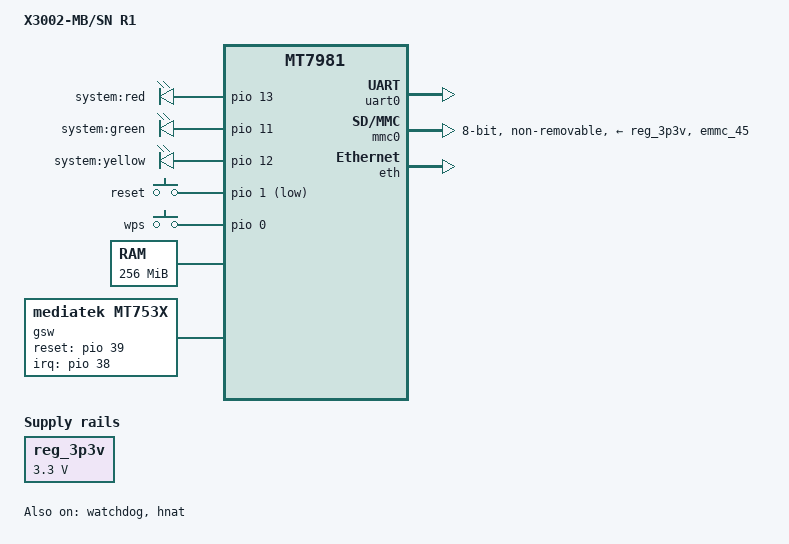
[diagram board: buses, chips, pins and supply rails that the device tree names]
/dts-v1/;
#include "mt7981.dtsi"
/ {
	model = "X3002-MB/SN R1";
	compatible = "sn,r1", "mediatek,mt7981";

	chosen {
		bootargs = "console=ttyS0,115200n1 loglevel=8  \
				earlycon=uart8250,mmio32,0x11002000 \
				root=PARTLABEL=rootfs rootfstype=squashfs,f2fs";
	};

	aliases {
		led-boot = &red_led;
		led-failsafe = &red_led;
		led-running = &green_led;
		led-upgrade = &yellow_led;
	};

	leds {
		compatible = "gpio-leds";

		red_led: red {
			label = "system:red";
			gpios = <&pio 13 GPIO_ACTIVE_HIGH>;
		};

		green_led: green {
			label = "system:green";
			gpios = <&pio 11 GPIO_ACTIVE_HIGH>;
		};

		yellow_led: yellow {
			label = "system:yellow";
			gpios = <&pio 12 GPIO_ACTIVE_HIGH>;
		};
	};

	gpio-keys {
		compatible = "gpio-keys";

		button-reset {
			label = "reset";
			linux,code = <KEY_RESTART>;
			gpios = <&pio 1 GPIO_ACTIVE_LOW>;
		};

		button-wps {
			label = "wps";
			linux,code = <KEY_WPS_BUTTON>;
			gpios = <&pio 0 GPIO_ACTIVE_HIGH>;
		};
	};

	memory {
		reg = <0 0x40000000 0 0x10000000>;
	};

	reg_3p3v: regulator-3p3v {
		compatible = "regulator-fixed";
		regulator-name = "fixed-3.3V";
		regulator-min-microvolt = <3300000>;
		regulator-max-microvolt = <3300000>;
		regulator-boot-on;
		regulator-always-on;
	};

	gsw: gsw@0 {
		compatible = "mediatek,mt753x";
		mediatek,ethsys = <&ethsys>;
		#address-cells = <1>;
		#size-cells = <0>;
	};
};

&uart0 {
	status = "okay";
};

&watchdog {
	status = "okay";
};

&mmc0 {
	bus-width = <8>;
	cap-mmc-highspeed;
	max-frequency = <52000000>;
	no-sd;
	no-sdio;
	non-removable;
	pinctrl-names = "default", "state_uhs";
	pinctrl-0 = <&mmc0_pins_default>;
	pinctrl-1 = <&mmc0_pins_uhs>;
	vmmc-supply = <&reg_3p3v>;
	non-removable;
	status = "okay";
};

&eth {
	status = "okay";

	gmac0: mac@0 {
		compatible = "mediatek,eth-mac";
		reg = <0>;
		phy-mode = "2500base-x";

		fixed-link {
			speed = <2500>;
			full-duplex;
			pause;
		};
	};

	mdio: mdio-bus {
		#address-cells = <1>;
		#size-cells = <0>;
	};
};

&gsw {
	mediatek,mdio = <&mdio>;
	mediatek,portmap = "wllll";
	mediatek,mdio_master_pinmux = <0>;
	reset-gpios = <&pio 39 0>;
	interrupt-parent = <&pio>;
	interrupts = <38 IRQ_TYPE_LEVEL_HIGH>;
	status = "okay";

	port5: port@5 {
		compatible = "mediatek,mt753x-port";
		reg = <5>;
		phy-mode = "sgmii";

		fixed-link {
			speed = <2500>;
			full-duplex;
		};
	};

	port6: port@6 {
		compatible = "mediatek,mt753x-port";
		mediatek,ssc-on;
		reg = <6>;
		phy-mode = "sgmii";

		fixed-link {
			speed = <2500>;
			full-duplex;
		};
	};
};

&hnat {
		mtketh-wan = "eth0.2";
		mtketh-ppd = "eth0.1";
		mtketh-lan = "eth0";
		mtketh-max-gmac = <1>;
		status = "okay";
};

&spi1 {
	pinctrl-names = "default";
	pinctrl-0 = <&spic_pins>;
	status = "disabled";
};

&pio {

	spic_pins: spi1-pins {
		mux {
			function = "spi";
			groups = "spi1_1";
		};
	};

	mmc0_pins_default: mmc0-pins-default {
		mux {
			function = "flash";
			groups = "emmc_45";
		};
	};

	mmc0_pins_uhs: mmc0-pins-uhs {
		mux {
			function = "flash";
			groups = "emmc_45";
		};
	};
};
